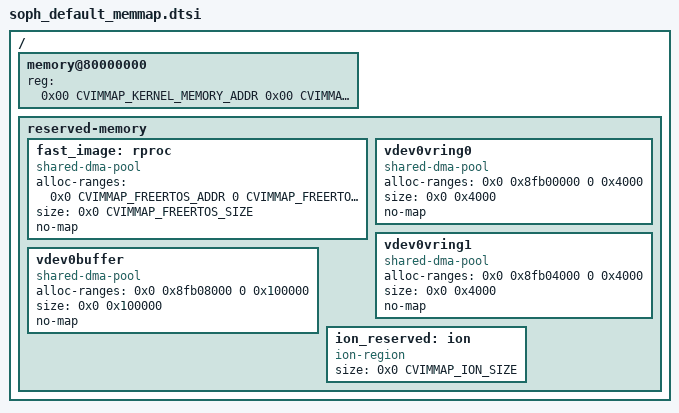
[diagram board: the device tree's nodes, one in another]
/ {
	memory@80000000 {
		device_type = "memory";
		reg = <0x00 CVIMMAP_KERNEL_MEMORY_ADDR 0x00 CVIMMAP_KERNEL_MEMORY_SIZE>;
	};


	reserved-memory {
		#size-cells = <0x2>;
		#address-cells = <0x2>;
		ranges;

		fast_image: rproc {
			compatible = "shared-dma-pool";
			alloc-ranges = <0x0 CVIMMAP_FREERTOS_ADDR 0 CVIMMAP_FREERTOS_SIZE>;
			size = <0x0 CVIMMAP_FREERTOS_SIZE>;
			no-map;
		};

		vdev0vring0: vdev0vring0 {
				compatible = "shared-dma-pool";
				alloc-ranges = <0x0 0x8fb00000 0 0x4000>;
				size = <0x0 0x4000>;
				no-map;
		};

		vdev0vring1: vdev0vring1 {
				compatible = "shared-dma-pool";
				alloc-ranges = <0x0 0x8fb04000 0 0x4000>;
				size = <0x0 0x4000>;
				no-map;
		};

		vdev0buffer: vdev0buffer {
			compatible = "shared-dma-pool";
			alloc-ranges = <0x0 0x8fb08000 0 0x100000>;
			size = <0x0 0x100000>;
			no-map;
		};
	
		ion_reserved: ion {
			compatible = "ion-region";
			size = <0x0 CVIMMAP_ION_SIZE>;
		};
	
	};
};
